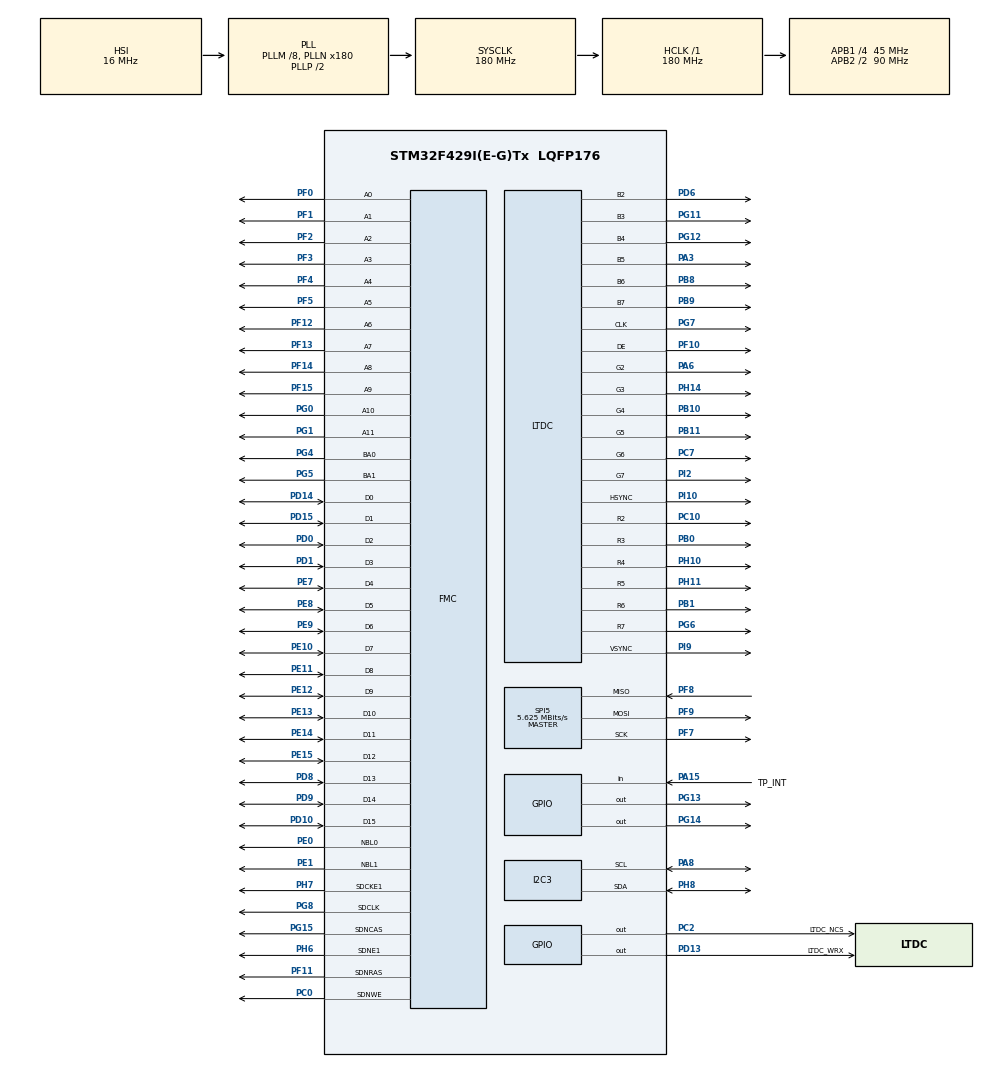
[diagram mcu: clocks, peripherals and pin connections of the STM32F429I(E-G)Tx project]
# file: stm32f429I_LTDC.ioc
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DMA2D.ColorMode=DMA2D_OUTPUT_RGB888
DMA2D.InputColorModeBackground=DMA2D_INPUT_RGB888
DMA2D.InputColorModeForeground=DMA2D_INPUT_RGB888
DMA2D.Mode=DMA2D_M2M_BLEND
FMC.CASLatency1=FMC_SDRAM_CAS_LATENCY_3
FMC.ExitSelfRefreshDelay1=7
FMC.LoadToActiveDelay1=2
FMC.RCDDelay1=2
FMC.RPDelay1=2
FMC.RPDelay2=2
FMC.ReadPipeDelay1=FMC_SDRAM_RPIPE_DELAY_1
FMC.ReadPipeDelay2=FMC_SDRAM_RPIPE_DELAY_1
FMC.RowCycleDelay1=7
FMC.RowCycleDelay2=7
FMC.SDClockPeriod1=FMC_SDRAM_CLOCK_PERIOD_2
FMC.SDClockPeriod2=FMC_SDRAM_CLOCK_PERIOD_2
FMC.SelfRefreshTime1=4
FMC.WriteRecoveryTime1=3
I2C3.OwnAddress=0x41
LTDC.ActiveH=320
LTDC.ActiveW=240
LTDC.Alpha_L0=255
LTDC.Green_L0=0
LTDC.HBP=21
LTDC.HFP=10
LTDC.HSync=9
LTDC.ImageHeight_L0=320
LTDC.ImageWidth_L0=240
LTDC.Layers=0
LTDC.PixelFormat_L0=LTDC_PIXEL_FORMAT_RGB888
LTDC.VBP=3
LTDC.VFP=4
LTDC.VSync=1
LTDC.WindowX1_L0=240
LTDC.WindowY1_L0=320
Mcu.Family=STM32F4
Mcu.Name=STM32F429I(E-G)Tx
Mcu.Package=LQFP176
NVIC.DMA2D_IRQn=true\:0\:0\:false\:false\:true\:true\:true\:true
NVIC.PriorityGroup=NVIC_PRIORITYGROUP_4
PA15.GPIO_Label=TP_INT
PA15.Signal=GPIO_Input
PA3.Mode=RGB666
PA3.Signal=LTDC_B5
PA6.Mode=RGB666
PA6.Signal=LTDC_G2
PA8.Mode=I2C
PA8.Signal=I2C3_SCL
PB0.Mode=RGB666
PB0.Signal=LTDC_R3
PB1.Mode=RGB666
PB1.Signal=LTDC_R6
PB10.Mode=RGB666
PB10.Signal=LTDC_G4
PB11.Mode=RGB666
PB11.Signal=LTDC_G5
PB8.Mode=RGB666
PB8.Signal=LTDC_B6
PB9.Mode=RGB666
PB9.Signal=LTDC_B7
PC0.Signal=FMC_SDNWE
PC10.Mode=RGB666
PC10.Signal=LTDC_R2
PC2.GPIO_Label=LTDC_NCS
PC2.GPIO_Speed=GPIO_SPEED_FREQ_HIGH
PC2.Signal=GPIO_Output
PC7.Mode=RGB666
PC7.Signal=LTDC_G6
PD0.Signal=FMC_D2_DA2
PD1.Signal=FMC_D3_DA3
PD10.Signal=FMC_D15_DA15
PD13.GPIO_Label=LTDC_WRX
PD13.GPIO_Speed=GPIO_SPEED_FREQ_HIGH
PD13.Signal=GPIO_Output
PD14.Signal=FMC_D0_DA0
PD15.Signal=FMC_D1_DA1
PD6.Mode=RGB666
PD6.Signal=LTDC_B2
PD8.Signal=FMC_D13_DA13
PD9.Signal=FMC_D14_DA14
PE0.Signal=FMC_NBL0
PE1.Signal=FMC_NBL1
PE10.Signal=FMC_D7_DA7
PE11.Signal=FMC_D8_DA8
PE12.Signal=FMC_D9_DA9
PE13.Signal=FMC_D10_DA10
PE14.Signal=FMC_D11_DA11
PE15.Signal=FMC_D12_DA12
PE7.Signal=FMC_D4_DA4
PE8.Signal=FMC_D5_DA5
PE9.Signal=FMC_D6_DA6
PF0.Signal=FMC_A0
PF1.Signal=FMC_A1
PF10.Mode=RGB666
PF10.Signal=LTDC_DE
PF11.Signal=FMC_SDNRAS
PF12.Signal=FMC_A6
PF13.Signal=FMC_A7
PF14.Signal=FMC_A8
PF15.Signal=FMC_A9
PF2.Signal=FMC_A2
PF3.Signal=FMC_A3
PF4.Signal=FMC_A4
PF5.Signal=FMC_A5
PF7.Mode=Full_Duplex_Master
PF7.Signal=SPI5_SCK
PF8.Mode=Full_Duplex_Master
PF8.Signal=SPI5_MISO
PF9.Mode=Full_Duplex_Master
PF9.Signal=SPI5_MOSI
PG0.Signal=FMC_A10
PG1.Signal=FMC_A11
PG11.Mode=RGB666
PG11.Signal=LTDC_B3
PG12.Mode=RGB666
PG12.Signal=LTDC_B4
PG13.Signal=GPIO_Output
PG14.Signal=GPIO_Output
PG15.Signal=FMC_SDNCAS
PG4.Signal=FMC_A14_BA0
PG5.Signal=FMC_A15_BA1
PG6.Mode=RGB666
PG6.Signal=LTDC_R7
PG7.Mode=RGB666
PG7.Signal=LTDC_CLK
PG8.Signal=FMC_SDCLK
PH10.Mode=RGB666
PH10.Signal=LTDC_R4
PH11.Mode=RGB666
PH11.Signal=LTDC_R5
PH14.Mode=RGB666
PH14.Signal=LTDC_G3
PH6.Mode=SdramChipSelect2_1
PH6.Signal=FMC_SDNE1
PH7.Mode=SdramChipSelect2_1
PH7.Signal=FMC_SDCKE1
PH8.Mode=I2C
PH8.Signal=I2C3_SDA
PI10.Mode=RGB666
PI10.Signal=LTDC_HSYNC
PI2.Mode=RGB666
PI2.Signal=LTDC_G7
PI9.Mode=RGB666
PI9.Signal=LTDC_VSYNC
ProjectManager.HeapSize=0x200
ProjectManager.StackSize=0x400
ProjectManager.TargetToolchain=STM32CubeIDE
RCC.48MHZClocksFreq_Value=90000000
RCC.AHBFreq_Value=180000000
RCC.APB1CLKDivider=RCC_HCLK_DIV4
RCC.APB1Freq_Value=45000000
RCC.APB1TimFreq_Value=90000000
RCC.APB2CLKDivider=RCC_HCLK_DIV2
RCC.APB2Freq_Value=90000000
RCC.APB2TimFreq_Value=180000000
RCC.CortexFreq_Value=180000000
RCC.HCLKFreq_Value=180000000
RCC.HSE_VALUE=25000000
RCC.HSI_VALUE=16000000
RCC.LSE_VALUE=32768
RCC.PLLM=8
RCC.PLLN=180
RCC.PLLSAIDivR=RCC_PLLSAIDIVR_4
RCC.PLLSAIN=60
RCC.SYSCLKFreq_VALUE=180000000
RCC.SYSCLKSource=RCC_SYSCLKSOURCE_PLLCLK
RCC.VCOOutputFreq_Value=360000000
SH.FMC_A0.0=FMC_A0,12b-sda1
SH.FMC_A1.0=FMC_A1,12b-sda1
SH.FMC_A10.0=FMC_A10,12b-sda1
SH.FMC_A11.0=FMC_A11,12b-sda1
SH.FMC_A14_BA0.0=FMC_BA0,FourSdramBanks1
SH.FMC_A15_BA1.0=FMC_BA1,FourSdramBanks1
SH.FMC_A2.0=FMC_A2,12b-sda1
SH.FMC_A3.0=FMC_A3,12b-sda1
SH.FMC_A4.0=FMC_A4,12b-sda1
SH.FMC_A5.0=FMC_A5,12b-sda1
SH.FMC_A6.0=FMC_A6,12b-sda1
SH.FMC_A7.0=FMC_A7,12b-sda1
SH.FMC_A8.0=FMC_A8,12b-sda1
SH.FMC_A9.0=FMC_A9,12b-sda1
SH.FMC_D0_DA0.0=FMC_D0,sd-16b-d1
SH.FMC_D10_DA10.0=FMC_D10,sd-16b-d1
SH.FMC_D11_DA11.0=FMC_D11,sd-16b-d1
SH.FMC_D12_DA12.0=FMC_D12,sd-16b-d1
SH.FMC_D13_DA13.0=FMC_D13,sd-16b-d1
SH.FMC_D14_DA14.0=FMC_D14,sd-16b-d1
SH.FMC_D15_DA15.0=FMC_D15,sd-16b-d1
SH.FMC_D1_DA1.0=FMC_D1,sd-16b-d1
SH.FMC_D2_DA2.0=FMC_D2,sd-16b-d1
SH.FMC_D3_DA3.0=FMC_D3,sd-16b-d1
SH.FMC_D4_DA4.0=FMC_D4,sd-16b-d1
SH.FMC_D5_DA5.0=FMC_D5,sd-16b-d1
SH.FMC_D6_DA6.0=FMC_D6,sd-16b-d1
SH.FMC_D7_DA7.0=FMC_D7,sd-16b-d1
SH.FMC_D8_DA8.0=FMC_D8,sd-16b-d1
SH.FMC_D9_DA9.0=FMC_D9,sd-16b-d1
SH.FMC_NBL0.0=FMC_NBL0,Sd2ByteEnable1
SH.FMC_NBL1.0=FMC_NBL1,Sd2ByteEnable1
SH.FMC_SDCLK.0=FMC_SDCLK,12b-sda1
SH.FMC_SDNCAS.0=FMC_SDNCAS,12b-sda1
SH.FMC_SDNRAS.0=FMC_SDNRAS,12b-sda1
SH.FMC_SDNWE.0=FMC_SDNWE,12b-sda1
SPI5.BaudRatePrescaler=SPI_BAUDRATEPRESCALER_16
SPI5.CalculateBaudRate=5.625 MBits/s
SPI5.Direction=SPI_DIRECTION_2LINES
SPI5.Mode=SPI_MODE_MASTER
SPI5.VirtualType=VM_MASTER
VP_DMA2D_VS_DMA2D.Mode=DMA2D_Activate
board=custom

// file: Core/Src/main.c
/* USER CODE BEGIN Header */
/**
  ******************************************************************************
  * @file           : main.c
  * @brief          : Main program body
  ******************************************************************************
  * @attention
  *
  * Copyright (c) 2022 STMicroelectronics.
  * All rights reserved.
  *
  * This software is licensed under terms that can be found in the LICENSE file
  * in the root directory of this software component.
  * If no LICENSE file comes with this software, it is provided AS-IS.
  *
  ******************************************************************************
  */
/* USER CODE END Header */
#include "main.h"
/* USER CODE BEGIN Includes */
#include "ltdc.h"
#include "sdram.h"
#include "touch.h"
#include "image.h"
/* USER CODE END Includes */

/* USER CODE BEGIN PTD */
#define LCD_FRAME_BUFFER       ((uint32_t)0xD0000000)
#define BUFFER_OFFSET          ((uint32_t)0x50000)
/* USER CODE END PTD */

DMA2D_HandleTypeDef hdma2d;

I2C_HandleTypeDef hi2c3;

LTDC_HandleTypeDef hltdc;

SPI_HandleTypeDef hspi5;

SDRAM_HandleTypeDef hsdram1;

void SystemClock_Config(void);
static void MX_GPIO_Init(void);
static void MX_DMA2D_Init(void);
static void MX_FMC_Init(void);
static void MX_I2C3_Init(void);
static void MX_SPI5_Init(void);
static void MX_LTDC_Init(void);

int main(void)
{
  /* USER CODE BEGIN 1 */
	uint8_t *dma2d_in1;
	uint8_t *dma2d_in2;

	dma2d_in1 = (uint8_t *) ((uint32_t)(3) * LCD_FRAME_BUFFER);
	dma2d_in2 = (uint8_t *) ((uint32_t)(4) * LCD_FRAME_BUFFER);
  /* USER CODE END 1 */

  /* MCU Configuration--------------------------------------------------------*/

  /* Reset of all peripherals, Initializes the Flash interface and the Systick. */
  HAL_Init();

  /* Configure the system clock */
  SystemClock_Config();

  /* Initialize all configured peripherals */
  MX_GPIO_Init();
  MX_DMA2D_Init();
  MX_FMC_Init();
  MX_I2C3_Init();
  MX_SPI5_Init();
  MX_LTDC_Init();
  /* USER CODE BEGIN 2 */
  SDRAM_init(&hsdram1);
  LCD_PowerOn();
  HAL_LTDC_SetAddress(&hltdc,(uint32_t) LCD_FRAME_BUFFER + BUFFER_OFFSET,0);
  TP_Config();

  LCD_FillScreen(0xFF0000);
  HAL_Delay(2000);
  LCD_FillScreen(0x0FF0FF);
  HAL_Delay(1000);
  LCD_Test();
  HAL_Delay(1000);
  LCD_FillScreen(LCD_COLOR_BLACK);
  LCD_FontsInit();
  LCD_SetFont(&Font24);
  LCD_SetTextColor(LCD_COLOR_YELLOW);
  LCD_SetBackColor(LCD_COLOR_BLUE);
  LCD_DrawChar(10, 10, (uint8_t) 'T');
  LCD_DrawChar(27, 10, (uint8_t) 'e');
  LCD_DrawChar(44, 10, (uint8_t) 's');
  LCD_DrawChar(61, 10, (uint8_t) 't');

  LCD_SetFont(&Font16);
  LCD_SetBackColor(LCD_COLOR_DARKBLUE);
  LCD_SetTextColor(LCD_COLOR_LIGHTRED);
  LCD_DrawString(10, 30, (uint8_t *)"Left 16", LEFT_MODE);

  LCD_SetFont(&Font8);
  LCD_SetBackColor(LCD_COLOR_DARKCYAN);
  LCD_SetTextColor(LCD_COLOR_MAGENTA);
  LCD_DrawString(10, 50, (uint8_t *)"Right 8", RIGHT_MODE);

  LCD_SetFont(&Font8);
  LCD_SetBackColor(LCD_COLOR_BLACK);
  LCD_SetTextColor(LCD_COLOR_CYAN);
  LCD_DrawString(10, 100, (uint8_t *)"Center 24", CENTER_MODE);

  LCD_SetTextColor(LCD_COLOR_DARKMAGENTA);
  LCD_DrawString(0, 200, (uint8_t *)"Left 24", LEFT_MODE);
  HAL_Delay(2000);
  LCD_SetFont(&Font20);
  LCD_SetTextColor(LCD_COLOR_ORANGE);
  LCD_FillScreen(0x00);
  LCD_DrawImage(0, 0, 320, 240, image);
  tp_state_t tp_state;
  char str[20] = {0};
  uint8_t v,w;
  /* USER CODE END 2 */

  /* Infinite loop */
  while (1)
  {
	  TP_GetState(&tp_state);
	  if (tp_state.touchDetected)
	  {
		  sprintf(str, "x=%03d, y=%03d", tp_state.x, tp_state.y);
//		  LCD_FillScreen(0x00);
		  LCD_DrawString(0,0, (uint8_t*)str, CENTER_MODE);
//		  LCD_DrawCross(tp_state.x, tp_state.y, LCD_COLOR_WHITE);
			if(tp_state.x >=33 && tp_state.x<=202 && tp_state.y>=63 && tp_state.y<=115)
			{
				if(v==1){
				HAL_GPIO_WritePin(GPIOG, GPIO_PIN_14, GPIO_PIN_SET);
				HAL_Delay(100);
				v=0;}

				if(v==0){
				HAL_GPIO_WritePin(GPIOG, GPIO_PIN_14, GPIO_PIN_RESET);
				HAL_Delay(100);
				v=1;}
			}

			if(tp_state.x >=33 && tp_state.x<=202 && tp_state.y>=216 && tp_state.y<=265)
			{
				if(w==1){
				HAL_GPIO_WritePin(GPIOG, GPIO_PIN_13, GPIO_PIN_SET);
				HAL_Delay(100);
				w=0;}

				if(w==0){
				HAL_GPIO_WritePin(GPIOG, GPIO_PIN_13, GPIO_PIN_RESET);
				HAL_Delay(100);
				w=1;}

			}

	  }
  }
}

void SystemClock_Config(void)
{
  RCC_OscInitTypeDef RCC_OscInitStruct = {0};
  RCC_ClkInitTypeDef RCC_ClkInitStruct = {0};

  /** Configure the main internal regulator output voltage
  */
  __HAL_RCC_PWR_CLK_ENABLE();
  __HAL_PWR_VOLTAGESCALING_CONFIG(PWR_REGULATOR_VOLTAGE_SCALE1);

  /** Initializes the RCC Oscillators according to the specified parameters
  * in the RCC_OscInitTypeDef structure.
  */
  RCC_OscInitStruct.OscillatorType = RCC_OSCILLATORTYPE_HSI;
  RCC_OscInitStruct.HSIState = RCC_HSI_ON;
  RCC_OscInitStruct.HSICalibrationValue = RCC_HSICALIBRATION_DEFAULT;
  RCC_OscInitStruct.PLL.PLLState = RCC_PLL_ON;
  RCC_OscInitStruct.PLL.PLLSource = RCC_PLLSOURCE_HSI;
  RCC_OscInitStruct.PLL.PLLM = 8;
  RCC_OscInitStruct.PLL.PLLN = 180;
  RCC_OscInitStruct.PLL.PLLP = RCC_PLLP_DIV2;
  RCC_OscInitStruct.PLL.PLLQ = 3;
  if (HAL_RCC_OscConfig(&RCC_OscInitStruct) != HAL_OK)
  {
    Error_Handler();
  }

  /** Activate the Over-Drive mode
  */
  if (HAL_PWREx_EnableOverDrive() != HAL_OK)
  {
    Error_Handler();
  }

  /** Initializes the CPU, AHB and APB buses clocks
  */
  RCC_ClkInitStruct.ClockType = RCC_CLOCKTYPE_HCLK|RCC_CLOCKTYPE_SYSCLK
                              |RCC_CLOCKTYPE_PCLK1|RCC_CLOCKTYPE_PCLK2;
  RCC_ClkInitStruct.SYSCLKSource = RCC_SYSCLKSOURCE_PLLCLK;
  RCC_ClkInitStruct.AHBCLKDivider = RCC_SYSCLK_DIV1;
  RCC_ClkInitStruct.APB1CLKDivider = RCC_HCLK_DIV4;
  RCC_ClkInitStruct.APB2CLKDivider = RCC_HCLK_DIV2;

  if (HAL_RCC_ClockConfig(&RCC_ClkInitStruct, FLASH_LATENCY_5) != HAL_OK)
  {
    Error_Handler();
  }
}

static void MX_DMA2D_Init(void)
{

  hdma2d.Instance = DMA2D;
  hdma2d.Init.Mode = DMA2D_M2M_BLEND;
  hdma2d.Init.ColorMode = DMA2D_OUTPUT_RGB888;
  hdma2d.Init.OutputOffset = 0;
  hdma2d.LayerCfg[0].InputOffset = 0;
  hdma2d.LayerCfg[0].InputColorMode = DMA2D_INPUT_RGB888;
  hdma2d.LayerCfg[0].AlphaMode = DMA2D_REPLACE_ALPHA;
  hdma2d.LayerCfg[0].InputAlpha = 0;
  hdma2d.LayerCfg[1].InputOffset = 0;
  hdma2d.LayerCfg[1].InputColorMode = DMA2D_INPUT_RGB888;
  hdma2d.LayerCfg[1].AlphaMode = DMA2D_REPLACE_ALPHA;
  hdma2d.LayerCfg[1].InputAlpha = 0;
  if (HAL_DMA2D_Init(&hdma2d) != HAL_OK)
  {
    Error_Handler();
  }
  if (HAL_DMA2D_ConfigLayer(&hdma2d, 0) != HAL_OK)
  {
    Error_Handler();
  }
  if (HAL_DMA2D_ConfigLayer(&hdma2d, 1) != HAL_OK)
  {
    Error_Handler();
  }

}

static void MX_I2C3_Init(void)
{

  hi2c3.Instance = I2C3;
  hi2c3.Init.ClockSpeed = 100000;
  hi2c3.Init.DutyCycle = I2C_DUTYCYCLE_2;
  hi2c3.Init.OwnAddress1 = 130;
  hi2c3.Init.AddressingMode = I2C_ADDRESSINGMODE_7BIT;
  hi2c3.Init.DualAddressMode = I2C_DUALADDRESS_DISABLE;
  hi2c3.Init.OwnAddress2 = 0;
  hi2c3.Init.GeneralCallMode = I2C_GENERALCALL_DISABLE;
  hi2c3.Init.NoStretchMode = I2C_NOSTRETCH_DISABLE;
  if (HAL_I2C_Init(&hi2c3) != HAL_OK)
  {
    Error_Handler();
  }

  /** Configure Analogue filter
  */
  if (HAL_I2CEx_ConfigAnalogFilter(&hi2c3, I2C_ANALOGFILTER_ENABLE) != HAL_OK)
  {
    Error_Handler();
  }

  /** Configure Digital filter
  */
  if (HAL_I2CEx_ConfigDigitalFilter(&hi2c3, 0) != HAL_OK)
  {
    Error_Handler();
  }

}

static void MX_LTDC_Init(void)
{

  LTDC_LayerCfgTypeDef pLayerCfg = {0};

  hltdc.Instance = LTDC;
  hltdc.Init.HSPolarity = LTDC_HSPOLARITY_AL;
  hltdc.Init.VSPolarity = LTDC_VSPOLARITY_AL;
  hltdc.Init.DEPolarity = LTDC_DEPOLARITY_AL;
  hltdc.Init.PCPolarity = LTDC_PCPOLARITY_IPC;
  hltdc.Init.HorizontalSync = 8;
  hltdc.Init.VerticalSync = 0;
  hltdc.Init.AccumulatedHBP = 29;
  hltdc.Init.AccumulatedVBP = 3;
  hltdc.Init.AccumulatedActiveW = 269;
  hltdc.Init.AccumulatedActiveH = 323;
  hltdc.Init.TotalWidth = 279;
  hltdc.Init.TotalHeigh = 327;
  hltdc.Init.Backcolor.Blue = 0;
  hltdc.Init.Backcolor.Green = 0;
  hltdc.Init.Backcolor.Red = 0;
  if (HAL_LTDC_Init(&hltdc) != HAL_OK)
  {
    Error_Handler();
  }
  pLayerCfg.WindowX0 = 0;
  pLayerCfg.WindowX1 = 240;
  pLayerCfg.WindowY0 = 0;
  pLayerCfg.WindowY1 = 320;
  pLayerCfg.PixelFormat = LTDC_PIXEL_FORMAT_RGB888;
  pLayerCfg.Alpha = 255;
  pLayerCfg.Alpha0 = 0;
  pLayerCfg.BlendingFactor1 = LTDC_BLENDING_FACTOR1_CA;
  pLayerCfg.BlendingFactor2 = LTDC_BLENDING_FACTOR2_CA;
  pLayerCfg.FBStartAdress = 0;
  pLayerCfg.ImageWidth = 240;
  pLayerCfg.ImageHeight = 320;
  pLayerCfg.Backcolor.Blue = 0;
  pLayerCfg.Backcolor.Green = 0;
  pLayerCfg.Backcolor.Red = 0;
  if (HAL_LTDC_ConfigLayer(&hltdc, &pLayerCfg, 0) != HAL_OK)
  {
    Error_Handler();
  }

}

static void MX_SPI5_Init(void)
{

  /* SPI5 parameter configuration*/
  hspi5.Instance = SPI5;
  hspi5.Init.Mode = SPI_MODE_MASTER;
  hspi5.Init.Direction = SPI_DIRECTION_2LINES;
  hspi5.Init.DataSize = SPI_DATASIZE_8BIT;
  hspi5.Init.CLKPolarity = SPI_POLARITY_LOW;
  hspi5.Init.CLKPhase = SPI_PHASE_1EDGE;
  hspi5.Init.NSS = SPI_NSS_SOFT;
  hspi5.Init.BaudRatePrescaler = SPI_BAUDRATEPRESCALER_16;
  hspi5.Init.FirstBit = SPI_FIRSTBIT_MSB;
  hspi5.Init.TIMode = SPI_TIMODE_DISABLE;
  hspi5.Init.CRCCalculation = SPI_CRCCALCULATION_DISABLE;
  hspi5.Init.CRCPolynomial = 10;
  if (HAL_SPI_Init(&hspi5) != HAL_OK)
  {
    Error_Handler();
  }

}

/* FMC initialization function */
static void MX_FMC_Init(void)
{

  FMC_SDRAM_TimingTypeDef SdramTiming = {0};

  /** Perform the SDRAM1 memory initialization sequence
  */
  hsdram1.Instance = FMC_SDRAM_DEVICE;
  /* hsdram1.Init */
  hsdram1.Init.SDBank = FMC_SDRAM_BANK2;
  hsdram1.Init.ColumnBitsNumber = FMC_SDRAM_COLUMN_BITS_NUM_8;
  hsdram1.Init.RowBitsNumber = FMC_SDRAM_ROW_BITS_NUM_12;
  hsdram1.Init.MemoryDataWidth = FMC_SDRAM_MEM_BUS_WIDTH_16;
  hsdram1.Init.InternalBankNumber = FMC_SDRAM_INTERN_BANKS_NUM_4;
  hsdram1.Init.CASLatency = FMC_SDRAM_CAS_LATENCY_3;
  hsdram1.Init.WriteProtection = FMC_SDRAM_WRITE_PROTECTION_DISABLE;
  hsdram1.Init.SDClockPeriod = FMC_SDRAM_CLOCK_PERIOD_2;
  hsdram1.Init.ReadBurst = FMC_SDRAM_RBURST_DISABLE;
  hsdram1.Init.ReadPipeDelay = FMC_SDRAM_RPIPE_DELAY_1;
  /* SdramTiming */
  SdramTiming.LoadToActiveDelay = 2;
  SdramTiming.ExitSelfRefreshDelay = 7;
  SdramTiming.SelfRefreshTime = 4;
  SdramTiming.RowCycleDelay = 7;
  SdramTiming.WriteRecoveryTime = 3;
  SdramTiming.RPDelay = 2;
  SdramTiming.RCDDelay = 2;

  if (HAL_SDRAM_Init(&hsdram1, &SdramTiming) != HAL_OK)
  {
    Error_Handler( );
  }

}

static void MX_GPIO_Init(void)
{
  GPIO_InitTypeDef GPIO_InitStruct = {0};

  /* GPIO Ports Clock Enable */
  __HAL_RCC_GPIOF_CLK_ENABLE();
  __HAL_RCC_GPIOC_CLK_ENABLE();
  __HAL_RCC_GPIOA_CLK_ENABLE();
  __HAL_RCC_GPIOB_CLK_ENABLE();
  __HAL_RCC_GPIOG_CLK_ENABLE();
  __HAL_RCC_GPIOE_CLK_ENABLE();
  __HAL_RCC_GPIOD_CLK_ENABLE();

  /*Configure GPIO pin Output Level */
  HAL_GPIO_WritePin(LTDC_NCS_GPIO_Port, LTDC_NCS_Pin, GPIO_PIN_SET);

  /*Configure GPIO pin Output Level */
  HAL_GPIO_WritePin(LTDC_WRX_GPIO_Port, LTDC_WRX_Pin, GPIO_PIN_RESET);

  /*Configure GPIO pin Output Level */
  HAL_GPIO_WritePin(GPIOG, GPIO_PIN_13|GPIO_PIN_14, GPIO_PIN_RESET);

  /*Configure GPIO pin : LTDC_NCS_Pin */
  GPIO_InitStruct.Pin = LTDC_NCS_Pin;
  GPIO_InitStruct.Mode = GPIO_MODE_OUTPUT_PP;
  GPIO_InitStruct.Pull = GPIO_NOPULL;
  GPIO_InitStruct.Speed = GPIO_SPEED_FREQ_HIGH;
  HAL_GPIO_Init(LTDC_NCS_GPIO_Port, &GPIO_InitStruct);

  /*Configure GPIO pin : LTDC_WRX_Pin */
  GPIO_InitStruct.Pin = LTDC_WRX_Pin;
  GPIO_InitStruct.Mode = GPIO_MODE_OUTPUT_PP;
  GPIO_InitStruct.Pull = GPIO_NOPULL;
  GPIO_InitStruct.Speed = GPIO_SPEED_FREQ_HIGH;
  HAL_GPIO_Init(LTDC_WRX_GPIO_Port, &GPIO_InitStruct);

  /*Configure GPIO pin : TP_INT_Pin */
  GPIO_InitStruct.Pin = TP_INT_Pin;
  GPIO_InitStruct.Mode = GPIO_MODE_INPUT;
  GPIO_InitStruct.Pull = GPIO_NOPULL;
  HAL_GPIO_Init(TP_INT_GPIO_Port, &GPIO_InitStruct);

  /*Configure GPIO pins : PG13 PG14 */
  GPIO_InitStruct.Pin = GPIO_PIN_13|GPIO_PIN_14;
  GPIO_InitStruct.Mode = GPIO_MODE_OUTPUT_PP;
  GPIO_InitStruct.Pull = GPIO_NOPULL;
  GPIO_InitStruct.Speed = GPIO_SPEED_FREQ_LOW;
  HAL_GPIO_Init(GPIOG, &GPIO_InitStruct);

}

void Error_Handler(void)
{
  __disable_irq();
  while (1)
  {
  }
}
